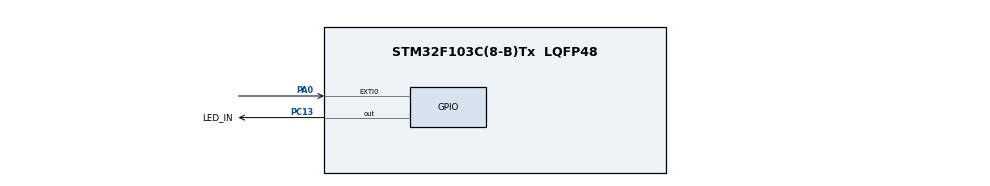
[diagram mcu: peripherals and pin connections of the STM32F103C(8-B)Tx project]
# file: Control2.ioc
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Mcu.Family=STM32F1
Mcu.Name=STM32F103C(8-B)Tx
Mcu.Package=LQFP48
NVIC.EXTI0_IRQn=true\:0\:0\:false\:false\:true\:true\:true
NVIC.PriorityGroup=NVIC_PRIORITYGROUP_4
NVIC.TIM3_IRQn=true\:0\:0\:false\:false\:true\:true\:true
NVIC.TIM4_IRQn=true\:0\:0\:false\:false\:true\:true\:true
PA0-WKUP.GPIO_ModeDefaultEXTI=GPIO_MODE_IT_FALLING
PA0-WKUP.GPIO_PuPd=GPIO_PULLUP
PA0-WKUP.Signal=GPXTI0
PA13.Mode=Serial_Wire
PA13.Signal=SYS_JTMS-SWDIO
PA14.Mode=Serial_Wire
PA14.Signal=SYS_JTCK-SWCLK
PC13-TAMPER-RTC.GPIO_Label=LED_IN
PC13-TAMPER-RTC.Signal=GPIO_Output
ProjectManager.HeapSize=0x200
ProjectManager.StackSize=0x400
ProjectManager.TargetToolchain=TrueSTUDIO
RCC.APB1Freq_Value=8000000
RCC.APB2Freq_Value=8000000
TIM3.Period=1000
TIM3.Prescaler=8000
TIM4.Period=1000
TIM4.Prescaler=8000
VP_TIM3_VS_ClockSourceINT.Mode=Internal
VP_TIM4_VS_ClockSourceINT.Mode=Internal
board=custom

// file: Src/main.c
/* USER CODE BEGIN Header */
/**
  ******************************************************************************
  * @file           : main.c
  * @brief          : Main program body
  ******************************************************************************
  * @attention
  *
  * <h2><center>&copy; Copyright (c) 2019 STMicroelectronics.
  * All rights reserved.</center></h2>
  *
  * This software component is licensed by ST under BSD 3-Clause license,
  * the "License"; You may not use this file except in compliance with the
  * License. You may obtain a copy of the License at:
  *                        opensource.org/licenses/BSD-3-Clause
  *
  ******************************************************************************
  */
/* USER CODE END Header */

#include "main.h"

TIM_HandleTypeDef htim3;
TIM_HandleTypeDef htim4;

/* USER CODE BEGIN PV */
volatile uint8_t itPiscou;
volatile uint8_t itPlace;
volatile uint8_t itSenoide;

/* USER CODE END PV */

void SystemClock_Config(void);
static void MX_GPIO_Init(void);
static void MX_TIM3_Init(void);
static void MX_TIM4_Init(void);

int main(void)
{

  /* MCU Configuration--------------------------------------------------------*/

  /* Reset of all peripherals, Initializes the Flash interface and the Systick. */
  HAL_Init();

  /* USER CODE BEGIN Init */
  itPiscou = 0;
  itPlace = 0;
  itSenoide = 0;

  /* USER CODE END Init */

  /* Configure the system clock */
  SystemClock_Config();

  /* Initialize all configured peripherals */
  MX_GPIO_Init();
  MX_TIM3_Init();
  MX_TIM4_Init();
  /* USER CODE BEGIN 2 */
  HAL_GPIO_TogglePin(LED_IN_GPIO_Port, LED_IN_Pin);
  /* USER CODE END 2 */

  /* Infinite loop */
  while (1)
  {
	  switch (itPiscou) {
		case 0:
			if(itSenoide)
			{
				HAL_TIM_Base_Start_IT(&htim3);
				itPiscou = 1;
			}
			break;
		case 1:
			if(itPlace == 1)
			{
				HAL_TIM_Base_Start_IT(&htim4);
				itPiscou = 2;
			}
			break;
		case 2:
			if(itPlace == 2)
			{
				HAL_TIM_Base_Stop_IT(&htim4);
				itPiscou = 0;
				itPlace = 0;
				itSenoide = 0;
			}
			break;
	}
    /* USER CODE BEGIN 3 */
  }
}

void SystemClock_Config(void)
{
  RCC_OscInitTypeDef RCC_OscInitStruct = {0};
  RCC_ClkInitTypeDef RCC_ClkInitStruct = {0};

  /** Initializes the CPU, AHB and APB busses clocks
  */
  RCC_OscInitStruct.OscillatorType = RCC_OSCILLATORTYPE_HSI;
  RCC_OscInitStruct.HSIState = RCC_HSI_ON;
  RCC_OscInitStruct.HSICalibrationValue = RCC_HSICALIBRATION_DEFAULT;
  RCC_OscInitStruct.PLL.PLLState = RCC_PLL_NONE;
  if (HAL_RCC_OscConfig(&RCC_OscInitStruct) != HAL_OK)
  {
    Error_Handler();
  }
  /** Initializes the CPU, AHB and APB busses clocks
  */
  RCC_ClkInitStruct.ClockType = RCC_CLOCKTYPE_HCLK|RCC_CLOCKTYPE_SYSCLK
                              |RCC_CLOCKTYPE_PCLK1|RCC_CLOCKTYPE_PCLK2;
  RCC_ClkInitStruct.SYSCLKSource = RCC_SYSCLKSOURCE_HSI;
  RCC_ClkInitStruct.AHBCLKDivider = RCC_SYSCLK_DIV1;
  RCC_ClkInitStruct.APB1CLKDivider = RCC_HCLK_DIV1;
  RCC_ClkInitStruct.APB2CLKDivider = RCC_HCLK_DIV1;

  if (HAL_RCC_ClockConfig(&RCC_ClkInitStruct, FLASH_LATENCY_0) != HAL_OK)
  {
    Error_Handler();
  }
}

static void MX_TIM3_Init(void)
{

  TIM_ClockConfigTypeDef sClockSourceConfig = {0};
  TIM_MasterConfigTypeDef sMasterConfig = {0};

  htim3.Instance = TIM3;
  htim3.Init.Prescaler = 8000;
  htim3.Init.CounterMode = TIM_COUNTERMODE_UP;
  htim3.Init.Period = 300;
  htim3.Init.ClockDivision = TIM_CLOCKDIVISION_DIV1;
  htim3.Init.AutoReloadPreload = TIM_AUTORELOAD_PRELOAD_DISABLE;
  if (HAL_TIM_Base_Init(&htim3) != HAL_OK)
  {
    Error_Handler();
  }
  sClockSourceConfig.ClockSource = TIM_CLOCKSOURCE_INTERNAL;
  if (HAL_TIM_ConfigClockSource(&htim3, &sClockSourceConfig) != HAL_OK)
  {
    Error_Handler();
  }
  sMasterConfig.MasterOutputTrigger = TIM_TRGO_RESET;
  sMasterConfig.MasterSlaveMode = TIM_MASTERSLAVEMODE_DISABLE;
  if (HAL_TIMEx_MasterConfigSynchronization(&htim3, &sMasterConfig) != HAL_OK)
  {
    Error_Handler();
  }

}

static void MX_TIM4_Init(void)
{

  TIM_ClockConfigTypeDef sClockSourceConfig = {0};
  TIM_MasterConfigTypeDef sMasterConfig = {0};

  htim4.Instance = TIM4;
  htim4.Init.Prescaler = 8000;
  htim4.Init.CounterMode = TIM_COUNTERMODE_UP;
  htim4.Init.Period = 100;
  htim4.Init.ClockDivision = TIM_CLOCKDIVISION_DIV1;
  htim4.Init.AutoReloadPreload = TIM_AUTORELOAD_PRELOAD_DISABLE;
  if (HAL_TIM_Base_Init(&htim4) != HAL_OK)
  {
    Error_Handler();
  }
  sClockSourceConfig.ClockSource = TIM_CLOCKSOURCE_INTERNAL;
  if (HAL_TIM_ConfigClockSource(&htim4, &sClockSourceConfig) != HAL_OK)
  {
    Error_Handler();
  }
  sMasterConfig.MasterOutputTrigger = TIM_TRGO_RESET;
  sMasterConfig.MasterSlaveMode = TIM_MASTERSLAVEMODE_DISABLE;
  if (HAL_TIMEx_MasterConfigSynchronization(&htim4, &sMasterConfig) != HAL_OK)
  {
    Error_Handler();
  }

}

static void MX_GPIO_Init(void)
{
  GPIO_InitTypeDef GPIO_InitStruct = {0};

  /* GPIO Ports Clock Enable */
  __HAL_RCC_GPIOC_CLK_ENABLE();
  __HAL_RCC_GPIOA_CLK_ENABLE();

  /*Configure GPIO pin Output Level */
  HAL_GPIO_WritePin(LED_IN_GPIO_Port, LED_IN_Pin, GPIO_PIN_RESET);

  /*Configure GPIO pin : LED_IN_Pin */
  GPIO_InitStruct.Pin = LED_IN_Pin;
  GPIO_InitStruct.Mode = GPIO_MODE_OUTPUT_PP;
  GPIO_InitStruct.Pull = GPIO_NOPULL;
  GPIO_InitStruct.Speed = GPIO_SPEED_FREQ_LOW;
  HAL_GPIO_Init(LED_IN_GPIO_Port, &GPIO_InitStruct);

  /*Configure GPIO pin : PA0 */
  GPIO_InitStruct.Pin = GPIO_PIN_0;
  GPIO_InitStruct.Mode = GPIO_MODE_IT_FALLING;
  GPIO_InitStruct.Pull = GPIO_PULLUP;
  HAL_GPIO_Init(GPIOA, &GPIO_InitStruct);

  /* EXTI interrupt init*/
  HAL_NVIC_SetPriority(EXTI0_IRQn, 0, 0);
  HAL_NVIC_EnableIRQ(EXTI0_IRQn);

}

void Error_Handler(void)
{
}

/************************ (C) COPYRIGHT STMicroelectronics *****END OF FILE****/
